# max32570 register map
Vendor: Maxim-Integrated; Series: ARMCM4; File version: 1.0
CPU: CM4 r2p1, little endian, MPU, FPU, 3 interrupt priority bits
Registers are 32-bit, read-write, reset 0x0 unless marked. A register's access mark holds for its fields unless they carry their own. Offsets are from the block's base; [hi:lo] are bit positions; {n}, {i} and the like mark numbered series.

## PT — Pulse Train
Base 0x4003C020
Same registers: PT8 ?, PT1 0x4003C040, PT2 0x4003C060, PT3 0x4003C080, PT4 0x4003C0A0, PT5 0x4003C0C0, PT6 0x4003C0E0, PT7 0x4003C100
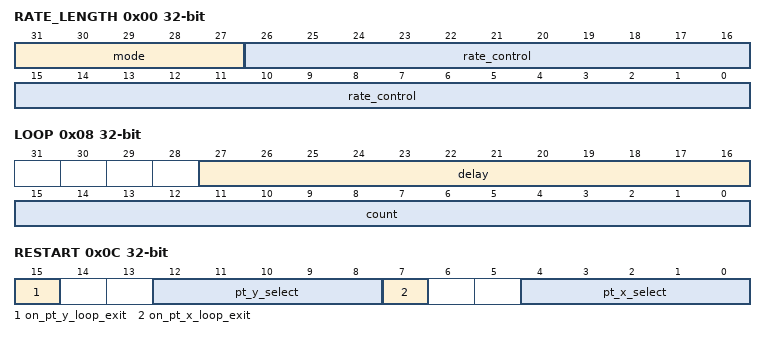
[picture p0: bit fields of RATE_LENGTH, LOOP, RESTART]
0x00 RATE_LENGTH — Pulse Train Configuration
  [31:27] mode — Pulse Train Output Mode/Train Length
    0=32_BIT (Pulse train, 32 bit pattern.); 1=SQUARE_WAVE (Square wave mode.); {v}={v}_BIT (Pulse train, {v} bit pattern.) (v=2..31)
  [26:0] rate_control — Pulse Train Enable and Rate Control. Set to 0 to disable the Pulse Train.
0x04 TRAIN — Write the repeating bit pattern that is shifted out, LSB first, when configured in Pulse Train mode. See PT_RATE_LENGTH.mode for setting the length.
0x08 LOOP — Pulse Train Loop Count
  [27:16] delay — Delay between loops of the Pulse Train in PT Peripheral Clock cycles
  [15:0] count — Number of loops for this pulse train to repeat.
0x0C RESTART — Pulse Train Auto-Restart Configuration.
  [15] on_pt_y_loop_exit — Enable Auto-Restart on PT Y Loop Exit
  [12:8] pt_y_select — Auto-Restart PT Y Select
  [7] on_pt_x_loop_exit — Enable Auto-Restart on PT X Loop Exit
  [4:0] pt_x_select — Auto-Restart PT X Select

## PTG — Pulse Train Generation
Base 0x4003C000
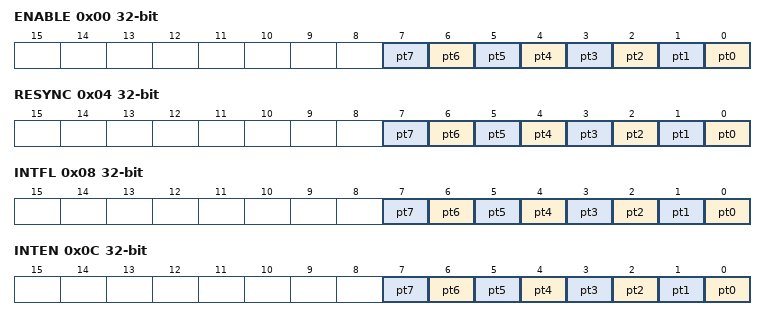
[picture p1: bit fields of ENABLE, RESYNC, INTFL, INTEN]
0x00 ENABLE — Global Enable/Disable Controls for All Pulse Trains
  [n] pt{n} (n=0..7) — Enable/Disable control for PT{n}
0x04 RESYNC — Global Resync (All Pulse Trains) Control
  [n] pt{n} (n=0..7) — Resync control for PT{n}
0x08 INTFL — Pulse Train Interrupt Flags
  [n] pt{n} (n=0..7) — Pulse Train {n} Stopped Interrupt Flag
0x0C INTEN — Pulse Train Interrupt Enable/Disable
  [n] pt{n} (n=0..7) — Pulse Train {n} Stopped Interrupt Enable/Disable
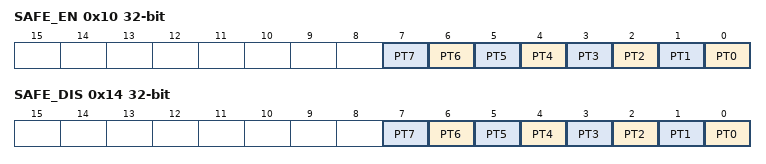
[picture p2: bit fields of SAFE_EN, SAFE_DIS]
0x10 SAFE_EN wo — Pulse Train Global Safe Enable.
  [n] PT{n} (n=0..7)
0x14 SAFE_DIS wo — Pulse Train Global Safe Disable.
  [n] PT{n} (n=0..7)

## RTC — Real Time Clock and Alarm.
Base 0x40006000
0x00 SEC reset not defined — RTC Second Counter. This register contains the 32-bit second counter.
  [31:0] SEC — Seconds Counter.
0x04 SSEC reset not defined — RTC Sub-second Counter. This counter increments at 256Hz. RTC_SEC is incremented when this register rolls over from 0xFF to 0x00.
  [11:0] SSEC — Sub-Seconds Counter (12-bit).
0x08 TODA reset not defined — Time-of-day Alarm.
  [19:0] TOD_ALARM
0x0C SSECA reset not defined — RTC sub-second alarm. This register contains the reload value for the sub-second alarm.
  [31:0] SSEC_ALARM — This register contains the reload value for the sub-second alarm.
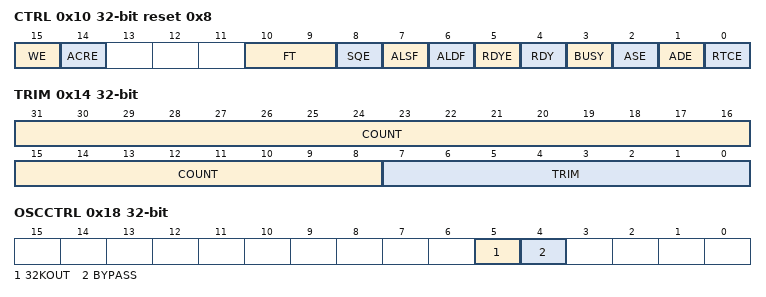
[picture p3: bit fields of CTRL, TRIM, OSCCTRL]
0x10 CTRL reset 0x8 (reset mask 0xFFFFFF38) — RTC Control Register.
  [15] WE — Write Enable. This register bit serves as a protection mechanism against unintentional writes to critical RTC bits.
    0=Ignored; 1=Allowed
  [14] ACRE — Asynchronous Counter Read Enable.
    0=Synchronous; 1=Asynchronous
  [10:9] FT — Frequency Output Selection. When SQE=1, these bits specify the output frequency on the SQW pin.
    0=freq1Hz (1 Hz (Compensated).); 1=freq512Hz (512 Hz (Compensated).); 2=freq4KHz (4 KHz.)
  [8] SQE — Square Wave Output Enable.
    0=dis (Disable.); 1=en (Enable.)
  [7] ALSF ro — Sub-second Alarm Interrupt Flag. This alarm is qualified as wake-up source to the processor.
    0=inactive (Not active.); 1=pending (Active.)
  [6] ALDF ro — Time-of-Day Alarm Interrupt Flag. This alarm is qualified as wake-up source to the processor.
    0=inactive (Not active.); 1=pending (Active.)
  [5] RDYE — RTC Ready Interrupt Enable.
    0=dis (Disable.); 1=en (Enable.)
  [4] RDY — RTC Ready. This bit is set to 1 by hardware when the RTC count registers update. It can be cleared to 0 by software at any time. It will also be cleared to 0 by hardware just prior to an update of the RTC count register.
    0=busy (Register has not updated.); 1=ready
  [3] BUSY ro — RTC Busy. This bit is set to 1 by hardware when changes to RTC registers required a synchronized version of the register to be in place. This bit is automatically cleared by hardware.
    0=idle; 1=busy
  [2] ASE — Alarm Sub-second Interrupt Enable. Change to this bit is effective only after BUSY is cleared from 1 to 0.
    0=dis (Disable.); 1=en (Enable.)
  [1] ADE — Alarm Time-of-Day Interrupt Enable. Change to this bit is effective only after BUSY is cleared from 1 to 0.
    0=dis (Disable.); 1=en (Enable.)
  [0] RTCE — Real Time Clock Enable. This bit enables the Real Time Clock. This bit can only be written when WE=1 and BUSY =0. Change to this bit is effective only after BUSY is cleared from 1 to 0.
    0=dis (Disable.); 1=en (Enable.)
0x14 TRIM reset not defined — RTC Trim Register.
  [31:8] COUNT — VBAT Timer Value. When RTC is running off of VBAT, this field is incremented every 32 seconds.
  [7:0] TRIM — RTC Trim. This register contains the 2's complement value that specifies the trim resolution. Each increment or decrement of the bit adds or subtracts 1ppm at each 4KHz clock value, with a maximum correction of +/- 127ppm.
0x18 OSCCTRL reset not defined — RTC Oscillator Control Register.
  [5] 32KOUT — RTC 32kHz Square Wave Output
    0=dis (Disable.); 1=en (Enable.)
  [4] BYPASS — RTC Crystal Bypass
    0=dis (Disable.); 1=en (Enable.)
